# DA14585 register map
Vendor: Dialog; Series: DA1458x; File version: 1.2
CPU: CM0 r1p0, little endian, MPU, FPU, 3 interrupt priority bits
Registers are 16-bit, read-write, reset 0x0 unless marked. A register's access mark holds for its fields unless they carry their own. Offsets are from the block's base; [hi:lo] are bit positions; {n}, {i} and the like mark numbered series.

## UART2 — UART2 registers
Base 0x50001100
0x00 UART2_RBR_THR_DLL_REG — Receive Buffer Register
  [7:0] RBR_THR_DLL — Receive Buffer Register: This register contains the data byte received on the serial input port (sin) in UART mode or the serial infrared input (sir_in) in infrared mode. The data in this register is valid only if the Data Ready (DR) bit in the Line status Register (LSR) is set. If FIFOs are disabled (FCR[0] set to zero), the data in the RBR must be read before the next data arrives, otherwise it will be overwritten, resulting in an overrun error. If FIFOs are enabled (FCR[0] set to one), this register accesses the head of the receive FIFO. If the receive FIFO is full and this register is not read before the next data character arrives, then the data already in the FIFO will be preserved but any incoming data will be lost. An overrun error will also occur. Transmit Holding Register: This register contains data to be transmitted on the serial output port (sout) in UART mode or the serial infrared output (sir_out_n) in infrared mode. Data should only be written to the THR when the THR Empty (THRE) bit (LSR[5]) is set. If FIFO's are disabled (FCR[0] set to zero) and THRE is set, writing a single character to the THR clears the THRE. Any additional writes to the THR before the THRE is set again causes the THR data to be overwritten. If FIFO's are enabled (FCR[0] set to one) and THRE is set, x number of characters of data may be written to the THR before the FIFO is full. The number x (default=16) is determined by the value of FIFO Depth that you set during configuration. Any attempt to write data when the FIFO is full results in the write data being lost. Divisor Latch (Low): This register makes up the lower 8-bits of a 16-bit, read/write, Divisor Latch register that contains the baud rate divisor for the UART. This register may only be accessed when the DLAB bit (LCR[7]) is set. The output baud rate is equal to the serial clock (sclk) frequency divided by sixteen times the value of the baud rate divisor, as follows: baud rate = (serial clock freq) / (16 * divisor) Note that with the Divisor Latch Registers (DLL and DLH) set to zero, the baud clock is disabled and no serial communications will occur. Also, once the DLL is set, at least 8 clock cycles of the slowest DW_apb_uart clock should be allowed to pass before transmitting or receiving data.
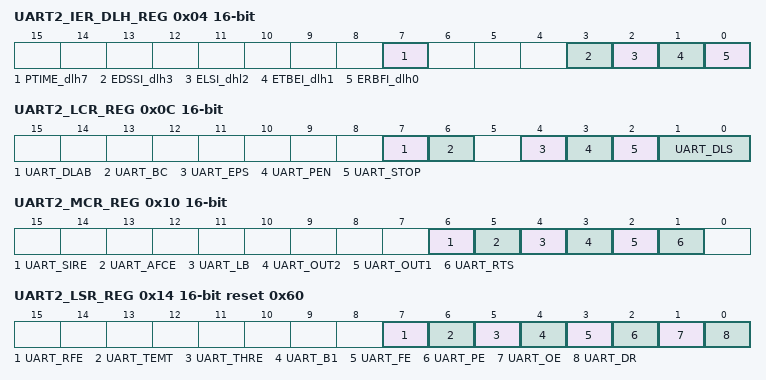
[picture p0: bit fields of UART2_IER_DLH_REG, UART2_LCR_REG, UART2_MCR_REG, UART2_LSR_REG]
0x04 UART2_IER_DLH_REG — Interrupt Enable Register
  [7] PTIME_dlh7 — Interrupt Enable Register: PTIME, Programmable THRE Interrupt Mode Enable. This is used to enable/disable the generation of THRE Interrupt. 0 = disabled 1 = enabled Divisor Latch (High): Bit[7] of the 8 bit DLH register.
  [3] EDSSI_dlh3 — Interrupt Enable Register: EDSSI, Enable Modem Status Interrupt. This is used to enable/disable the generation of Modem Status Interrupt. This is the fourth highest priority interrupt. 0 = disabled 1 = enabled Divisor Latch (High): Bit[3] of the 8 bit DLH register
  [2] ELSI_dhl2 — Interrupt Enable Register: ELSI, Enable Receiver Line Status Interrupt. This is used to enable/disable the generation of Receiver Line Status Interrupt. This is the highest priority interrupt. 0 = disabled 1 = enabled Divisor Latch (High): Bit[2] of the 8 bit DLH register.
  [1] ETBEI_dlh1 — Interrupt Enable Register: ETBEI, Enable Transmit Holding Register Empty Interrupt. This is used to enable/disable the generation of Transmitter Holding Register Empty Interrupt. This is the third highest priority interrupt. 0 = disabled 1 = enabled Divisor Latch (High): Bit[1] of the 8 bit DLH register.
  [0] ERBFI_dlh0 — Interrupt Enable Register: ERBFI, Enable Received Data Available Interrupt. This is used to enable/disable the generation of Received Data Available Interrupt and the Character Timeout Interrupt (if in FIFO mode and FIFO's enabled). These are the second highest priority interrupts. 0 = disabled 1 = enabled Divisor Latch (High): Bit[0] of the 8 bit DLH register.
0x08 UART2_IIR_FCR_REG — Interrupt Identification Register/FIFO Control Register
  [15:0] IIR_FCR — Interrupt Identification Register, reading this register; FIFO Control Register, writing to this register. Interrupt Identification Register: Bits[7:6], FIFO's Enabled (or FIFOSE): This is used to indicate whether the FIFO's are enabled or disabled. 00 = disabled. 11 = enabled. Bits[3:0], Interrupt ID (or IID): This indicates the highest priority pending interrupt which can be one of the following types: 0000 = modem status. 0001 = no interrupt pending. 0010 = THR empty. 0100 = received data available. 0110 = receiver line status. 0111 = busy detect. 1100 = character timeout. Bits[7:6], RCVR Trigger (or RT):. This is used to select the trigger level in the receiver FIFO at which the Received Data Available Interrupt will be generated. In auto flow control mode it is used to determine when the rts_n signal will be de-asserted. It also determines when the dma_rx_req_n signal will be asserted when in certain modes of operation. The following trigger levels are supported: 00 = 1 character in the FIFO 01 = FIFO 1/4 full 10 = FIFO 1/2 full 11 = FIFO 2 less than full Bits[5:4], TX Empty Trigger (or TET): This is used to select the empty threshold level at which the THRE Interrupts will be generated when the mode is active. It also determines when the dma_tx_req_n signal will be asserted when in certain modes of operation. The following trigger levels are supported: 00 = FIFO empty 01 = 2 characters in the FIFO 10 = FIFO 1/4 full 11 = FIFO 1/2 full Bit[3], DMA Mode (or DMAM): This determines the DMA signalling mode used for the dma_tx_req_n and dma_rx_req_n output signals. 0 = mode 0 1 = mode 1 Bit[2], XMIT FIFO Reset (or XFIFOR): This resets the control portion of the transmit FIFO and treats the FIFO as empty. Note that this bit is 'self-clearing' and it is not necessary to clear this bit. Bit[1], RCVR FIFO Reset (or RFIFOR): This resets the control portion of the receive FIFO and treats the FIFO as empty. Note that this bit is 'self-clearing' and it is not necessary to clear this bit. Bit[0], FIFO Enable (or FIFOE): This enables/disables the transmit (XMIT) and receive (RCVR) FIFO's. Whenever the value of this bit is changed both the XMIT and RCVR controller portion of FIFO's will be reset.
0x0C UART2_LCR_REG — Line Control Register
  [7] UART_DLAB — Divisor Latch Access Bit. This bit is used to enable reading and writing of the Divisor Latch register (DLL and DLH) to set the baud rate of the UART. This bit must be cleared after initial baud rate setup in order to access other registers.
  [6] UART_BC — Break Control Bit. This is used to cause a break condition to be transmitted to the receiving device. If set to one the serial output is forced to the spacing (logic 0) state. When not in Loopback Mode, as determined by MCR[4], the sout line is forced low until the Break bit is cleared. If active (MCR[6] set to one) the sir_out_n line is continuously pulsed. When in Loopback Mode, the break condition is internally looped back to the receiver and the sir_out_n line is forced low.
  [4] UART_EPS — Even Parity Select. This is used to select between even and odd parity, when parity is enabled (PEN set to one). If set to one, an even number of logic 1s is transmitted or checked. If set to zero, an odd number of logic 1s is transmitted or checked.
  [3] UART_PEN — Parity Enable. This bit is used to enable and disable parity generation and detection in transmitted and received serial character respectively. 0 = parity disabled 1 = parity enabled
  [2] UART_STOP — Number of stop bits. This is used to select the number of stop bits per character that the peripheral transmits and receives. If set to zero, one stop bit is transmitted in the serial data. If set to one and the data bits are set to 5 (LCR[1:0] set to zero) one and a half stop bits is transmitted. Otherwise, two stop bits are transmitted. Note that regardless of the number of stop bits selected, the receiver checks only the first stop bit. 0 = 1 stop bit 1 = 1.5 stop bits when DLS (LCR[1:0]) is zero, else 2 stop bit
  [1:0] UART_DLS — Data Length Select. This is used to select the number of data bits per character that the peripheral transmits and receives. The number of bit that may be selected areas follows: 00 = 5 bits 01 = 6 bits 10 = 7 bits 11 = 8 bits
0x10 UART2_MCR_REG — Modem Control Register
  [6] UART_SIRE — SIR Mode Enable. This is used to enable or disable the IrDA SIR Mode features as described in 'IrDA 1.0 SIR Protocol' on page 53. 0 = IrDA SIR Mode disabled. 1 = IrDA SIR Mode enabled .
  [5] UART_AFCE — Auto Flow Control Enable. When FIFOs are enabled and the Auto Flow Control Enable (AFCE) bit is set, hardware Auto Flow Control is enabled via CTS and RTS. 0 = Auto Flow Control Mode disabled 1 = Auto Flow Control Mode enabled
  [4] UART_LB — LoopBack Bit. This is used to put the UART into a diagnostic mode for test purposes. If operating in UART mode (SIR_MODE not active, MCR[6] set to zero), data on the sout line is held high, while serial data output is looped back to the sin line, internally. In this mode all the interrupts are fully functional. Also, in loopback mode, the modem control inputs (dsr_n, cts_n, ri_n, dcd_n) are disconnected and the modem control outputs (dtr_n, rts_n, out1_n, out2_n) are looped back to the inputs, internally. If operating in infrared mode (SIR_MODE active, MCR[6] set to one), data on the sir_out_n line is held low, while serial data output is inverted and looped back to the sir_in line.
  [3] UART_OUT2 — OUT2. This is used to directly control the user-designated Output2 (out2_n) output. The value written to this location is inverted and driven out on out2_n, that is: 0 = out2_n de-asserted (logic 1) 1 = out2_n asserted (logic 0) Note that in Loopback mode (MCR[4] set to one), the out2_n output is held inactive high while the value of this location is internally looped back to an input.
  [2] UART_OUT1 — OUT1. This is used to directly control the user-designated Output1 (out1_n) output. The value written to this location is inverted and driven out on out1_n, that is: 0 = out1_n de-asserted (logic 1) 1 = out1_n asserted (logic 0) Note that in Loopback mode (MCR[4] set to one), the out1_n output is held inactive high while the value of this location is internally looped back to an input.
  [1] UART_RTS — Request to Send. This is used to directly control the Request to Send (rts_n) output. The Request To Send (rts_n) output is used to inform the modem or data set that the UART is ready to exchange data. When Auto Flow Control is disabled (MCR[5] set to zero), the rts_n signal is set low by programming MCR[1] (RTS) to a high. When Auto Flow Control is enabled (MCR[5] set to one) and FIFOs are enabled (FCR[0] set to one), the rts_n output is controlled in the same way, but is also gated with the receiver FIFO threshold trigger (rts_n is inactive high when above the threshold). The rts_n signal is de-asserted when MCR[1] is set low. Note that in Loopback mode (MCR[4] set to one), the rts_n output is held inactive (high) while the value of this location is internally looped back to an input.
0x14 UART2_LSR_REG reset 0x60 — Line Status Register
  [7] UART_RFE ro — Receiver FIFO Error bit. This bit is only relevant when FIFOs are enabled (FCR[0] set to one). This is used to indicate if there is at least one parity error, framing error, or break indication in the FIFO. 0 = no error in RX FIFO 1 = error in RX FIFO This bit is cleared when the LSR is read and the character with the error is at the top of the receiver FIFO and there are no subsequent errors in the FIFO.
  [6] UART_TEMT ro — Transmitter Empty bit. If FIFOs enabled (FCR[0] set to one), this bit is set whenever the Transmitter Shift Register and the FIFO are both empty. If FIFOs are disabled, this bit is set whenever the Transmitter Holding Register and the Transmitter Shift Register are both empty.
  [5] UART_THRE ro — Transmit Holding Register Empty bit. If THRE mode is disabled (IER[7] set to zero) and regardless of FIFO's being implemented/enabled or not, this bit indicates that the THR or TX FIFO is empty. This bit is set whenever data is transferred from the THR or TX FIFO to the transmitter shift register and no new data has been written to the THR or TX FIFO. This also causes a THRE Interrupt to occur, if the THRE Interrupt is enabled. If both modes are active (IER[7] set to one and FCR[0] set to one respectively), the functionality is switched to indicate the transmitter FIFO is full, and no longer controls THRE interrupts, which are then controlled by the FCR[5:4] threshold setting.
  [4] UART_B1 ro — Break Interrupt bit. This is used to indicate the detection of a break sequence on the serial input data. If in UART mode (SIR_MODE == Disabled), it is set whenever the serial input, sin, is held in a logic '0' state for longer than the sum of start time + data bits + parity + stop bits. If in infrared mode (SIR_MODE == Enabled), it is set whenever the serial input, sir_in, is continuously pulsed to logic '0' for longer than the sum of start time + data bits + parity + stop bits. A break condition on serial input causes one and only one character, consisting of all zeros, to be received by the UART. In the FIFO mode, the character associated with the break condition is carried through the FIFO and is revealed when the character is at the top of the FIFO. Reading the LSR clears the BI bit. In the non-FIFO mode, the BI indication occurs immediately and persists until the LSR is read.
  [3] UART_FE ro — Framing Error bit. This is used to indicate the occurrence of a framing error in the receiver. A framing error occurs when the receiver does not detect a valid STOP bit in the received data. In the FIFO mode, since the framing error is associated with a character received, it is revealed when the character with the framing error is at the top of the FIFO. When a framing error occurs, the UART tries to resynchronize. It does this by assuming that the error was due to the start bit of the next character and then continues receiving the other bit i.e. data, and/or parity and stop. It should be noted that the Framing Error (FE) bit (LSR[3]) is set if a break interrupt has occurred, as indicated by Break Interrupt (BI) bit (LSR[4]). 0 = no framing error 1 = framing error Reading the LSR clears the FE bit.
  [2] UART_PE ro — Parity Error bit. This is used to indicate the occurrence of a parity error in the receiver if the Parity Enable (PEN) bit (LCR[3]) is set. In the FIFO mode, since the parity error is associated with a character received, it is revealed when the character with the parity error arrives at the top of the FIFO. It should be noted that the Parity Error (PE) bit (LSR[2]) is set if a break interrupt has occurred, as indicated by Break Interrupt (BI) bit (LSR[4]). 0 = no parity error 1 = parity error Reading the LSR clears the PE bit.
  [1] UART_OE ro — Overrun error bit. This is used to indicate the occurrence of an overrun error. This occurs if a new data character was received before the previous data was read. In the non-FIFO mode, the OE bit is set when a new character arrives in the receiver before the previous character was read from the RBR. When this happens, the data in the RBR is overwritten. In the FIFO mode, an overrun error occurs when the FIFO is full and a new character arrives at the receiver. The data in the FIFO is retained and the data in the receive shift register is lost. 0 = no overrun error 1 = overrun error Reading the LSR clears the OE bit.
  [0] UART_DR ro — Data Ready bit. This is used to indicate that the receiver contains at least one character in the RBR or the receiver FIFO. 0 = no data ready 1 = data ready This bit is cleared when the RBR is read in non-FIFO mode, or when the receiver FIFO is empty, in FIFO mode.
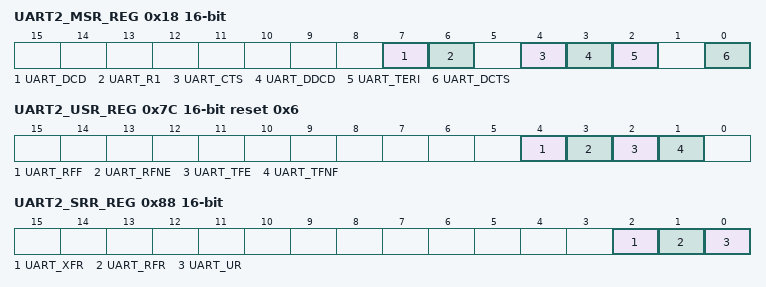
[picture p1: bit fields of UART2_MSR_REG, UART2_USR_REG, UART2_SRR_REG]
0x18 UART2_MSR_REG — Modem Status Register
  [7] UART_DCD ro — Data Carrier Detect. This is used to indicate the current state of the modem control line dcd_n. This bit is the complement of dcd_n. When the Data Carrier Detect input (dcd_n) is asserted it is an indication that the carrier has been detected by the modem or data set. 0 = dcd_n input is de-asserted (logic 1) 1 = dcd_n input is asserted (logic 0) In Loopback Mode (MCR[4] set to one), DCD is the same as MCR[3] (Out2).
  [6] UART_R1 ro — Ring Indicator. This is used to indicate the current state of the modem control line ri_n. This bit is the complement of ri_n. When the Ring Indicator input (ri_n) is asserted it is an indication that a telephone ringing signal has been received by the modem or data set. 0 = ri_n input is de-asserted (logic 1) 1 = ri_n input is asserted (logic 0) In Loopback Mode (MCR[4] set to one), RI is the same as MCR[2] (Out1).
  [4] UART_CTS ro — Clear to Send. This is used to indicate the current state of the modem control line cts_n. This bit is the complement of cts_n. When the Clear to Send input (cts_n) is asserted it is an indication that the modem or data set is ready to exchange data with the UART Ctrl. 0 = cts_n input is de-asserted (logic 1) 1 = cts_n input is asserted (logic 0) In Loopback Mode (MCR[4] = 1), CTS is the same as MCR[1] (RTS).
  [3] UART_DDCD ro — Delta Data Carrier Detect. This is used to indicate that the modem control line dcd_n has changed since the last time the MSR was read. 0 = no change on dcd_n since last read of MSR 1 = change on dcd_n since last read of MSR Reading the MSR clears the DDCD bit. In Loopback Mode (MCR[4] = 1), DDCD reflects changes on MCR[3] (Out2). Note, if the DDCD bit is not set and the dcd_n signal is asserted (low) and a reset occurs (software or otherwise), then the DDCD bit is set when the reset is removed if the dcd_n signal remains asserted.
  [2] UART_TERI ro — Trailing Edge of Ring Indicator. This is used to indicate that a change on the input ri_n (from an active-low to an inactive-high state) has occurred since the last time the MSR was read. 0 = no change on ri_n since last read of MSR 1 = change on ri_n since last read of MSR Reading the MSR clears the TERI bit. In Loopback Mode (MCR[4] = 1), TERI reflects when MCR[2] (Out1) has changed state from a high to a low.
  [0] UART_DCTS ro — Delta Clear to Send. This is used to indicate that the modem control line cts_n has changed since the last time the MSR was read. 0 = no change on cts_n since last read of MSR 1 = change on cts_n since last read of MSR Reading the MSR clears the DCTS bit. In Loopback Mode (MCR[4] = 1), DCTS reflects changes on MCR[1] (RTS). Note, if the DCTS bit is not set and the cts_n signal is asserted (low) and a reset occurs (software or otherwise), then the DCTS bit is set when the reset is removed if the cts_n signal remains asserted.
0x1C UART2_SCR_REG — Scratchpad Register
  [7:0] UART_SCRATCH_PAD — This register is for programmers to use as a temporary storage space. It has no defined purpose in the UART Ctrl.
0x20 UART2_LPDLL_REG — Low Power Divisor Latch Low
  [7:0] UART_LPDLL — This register makes up the lower 8-bits of a 16-bit, read/write, Low Power Divisor Latch register that contains the baud rate divisor for the UART, which must give a baud rate of 115.2K. This is required for SIR Low Power (minimum pulse width) detection at the receiver. This register may be accessed only when the DLAB bit (LCR[7]) is set. The output low-power baud rate is equal to the serial clock (sclk) frequency divided by sixteen times the value of the baud rate divisor, as follows: Low power baud rate = (serial clock frequency)/(16* divisor) Therefore, a divisor must be selected to give a baud rate of 115.2K. NOTE: When the Low Power Divisor Latch registers (LPDLL and LPDLH) are set to 0, the low-power baud clock is disabled and no low-power pulse detection (or any pulse detection) occurs at the receiver. Also, once the LPDLL is set, at least eight clock cycles of the slowest UART Ctrl clock should be allowed to pass before transmitting or receiving data.
0x24 UART2_LPDLH_REG — Low Power Divisor Latch High
  [7:0] UART_LPDLH — This register makes up the upper 8-bits of a 16-bit, read/write, Low Power Divisor Latch register that contains the baud rate divisor for the UART, which must give a baud rate of 115.2K. This is required for SIR Low Power (minimum pulse width) detection at the receiver. This register may be accessed only when the DLAB bit (LCR[7]) is set. The output low-power baud rate is equal to the serial clock (sclk) frequency divided by sixteen times the value of the baud rate divisor, as follows: Low power baud rate = (serial clock frequency)/(16* divisor) Therefore, a divisor must be selected to give a baud rate of 115.2K. NOTE: When the Low Power Divisor Latch registers (LPDLL and LPDLH) are set to 0, the low-power baud clock is disabled and no low-power pulse detection (or any pulse detection) occurs at the receiver. Also, once the LPDLH is set, at least eight clock cycles of the slowest UART Ctrl clock should be allowed to pass before transmitting or receiving data.
{0x30+4i} UART2_SRBR_STHR{i}_REG (i=0..15) — Shadow Receive/Transmit Buffer Register
  [7:0] SRBR_STHRx — Shadow Receive Buffer Register x: This is a shadow register for the RBR and has been allocated sixteen 32-bit locations so as to accommodate burst accesses from the master. This register contains the data byte received on the serial input port (sin) in UART mode or the serial infrared input (sir_in) in infrared mode. The data in this register is valid only if the Data Ready (DR) bit in the Line status Register (LSR) is set. If FIFOs are disabled (FCR[0] set to zero), the data in the RBR must be read before the next data arrives, otherwise it will be overwritten, resulting in an overrun error. If FIFOs are enabled (FCR[0] set to one), this register accesses the head of the receive FIFO. If the receive FIFO is full and this register is not read before the next data character arrives, then the data already in the FIFO will be preserved but any incoming data will be lost. An overrun error will also occur. Shadow Transmit Holding Register 0: This is a shadow register for the THR and has been allocated sixteen 32-bit locations so as to accommodate burst accesses from the master. This register contains data to be transmitted on the serial output port (sout) in UART mode or the serial infrared output (sir_out_n) in infrared mode. Data should only be written to the THR when the THR Empty (THRE) bit (LSR[5]) is set. If FIFO's are disabled (FCR[0] set to zero) and THRE is set, writing a single character to the THR clears the THRE. Any additional writes to the THR before the THRE is set again causes the THR data to be overwritten. If FIFO's are enabled (FCR[0] set to one) and THRE is set, x number of characters of data may be written to the THR before the FIFO is full. The number x (default=16) is determined by the value of FIFO Depth that you set during configuration. Any attempt to write data when the FIFO is full results in the write data being lost.
0x7C UART2_USR_REG reset 0x6 — UART Status register.
  [4] UART_RFF ro — Receive FIFO Full. This is used to indicate that the receive FIFO is completely full. 0 = Receive FIFO not full 1 = Receive FIFO Full This bit is cleared when the RX FIFO is no longer full.
  [3] UART_RFNE ro — Receive FIFO Not Empty. This is used to indicate that the receive FIFO contains one or more entries. 0 = Receive FIFO is empty 1 = Receive FIFO is not empty This bit is cleared when the RX FIFO is empty.
  [2] UART_TFE ro — Transmit FIFO Empty. This is used to indicate that the transmit FIFO is completely empty. 0 = Transmit FIFO is not empty 1 = Transmit FIFO is empty This bit is cleared when the TX FIFO is no longer empty.
  [1] UART_TFNF ro — Transmit FIFO Not Full. This is used to indicate that the transmit FIFO in not full. 0 = Transmit FIFO is full 1 = Transmit FIFO is not full This bit is cleared when the TX FIFO is full.
0x80 UART2_TFL_REG — Transmit FIFO Level
  [15:0] UART_TRANSMIT_FIFO_LEVEL ro — Transmit FIFO Level. This is indicates the number of data entries in the transmit FIFO.
0x84 UART2_RFL_REG — Receive FIFO Level.
  [15:0] UART_RECEIVE_FIFO_LEVEL ro — Receive FIFO Level. This is indicates the number of data entries in the receive FIFO.
0x88 UART2_SRR_REG — Software Reset Register.
  [2] UART_XFR wo — XMIT FIFO Reset. This is a shadow register for the XMIT FIFO Reset bit (FCR[2]). This can be used to remove the burden on software having to store previously written FCR values (which are pretty static) just to reset the transmit FIFO. This resets the control portion of the transmit FIFO and treats the FIFO as empty. Note that this bit is 'self-clearing'. It is not necessary to clear this bit.
  [1] UART_RFR wo — RCVR FIFO Reset. This is a shadow register for the RCVR FIFO Reset bit (FCR[1]). This can be used to remove the burden on software having to store previously written FCR values (which are pretty static) just to reset the receive FIFO This resets the control portion of the receive FIFO and treats the FIFO as empty. Note that this bit is 'self-clearing'. It is not necessary to clear this bit.
  [0] UART_UR wo — UART Reset. This asynchronously resets the UART Ctrl and synchronously removes the reset assertion. For a two clock implementation both pclk and sclk domains are reset.
0x8C UART2_SRTS_REG — Shadow Request to Send
  [0] UART_SHADOW_REQUEST_TO_SEND — Shadow Request to Send. This is a shadow register for the RTS bit (MCR[1]), this can be used to remove the burden of having to perform a read-modify-write on the MCR. This is used to directly control the Request to Send (rts_n) output. The Request To Send (rts_n) output is used to inform the modem or data set that the UART Ctrl is ready to exchange data. When Auto Flow Control is disabled (MCR[5] = 0), the rts_n signal is set low by programming MCR[1] (RTS) to a high. When Auto Flow Control is enabled (MCR[5] = 1) and FIFOs are enabled (FCR[0] = 1), the rts_n output is controlled in the same way, but is also gated with the receiver FIFO threshold trigger (rts_n is inactive high when above the threshold). Note that in Loopback mode (MCR[4] = 1), the rts_n output is held inactive-high while the value of this location is internally looped back to an input.
0x90 UART2_SBCR_REG — Shadow Break Control Register
  [0] UART_SHADOW_BREAK_CONTROL — Shadow Break Control Bit. This is a shadow register for the Break bit (LCR[6]), this can be used to remove the burden of having to performing a read modify write on the LCR. This is used to cause a break condition to be transmitted to the receiving device. If set to one the serial output is forced to the spacing (logic 0) state. When not in Loopback Mode, as determined by MCR[4], the sout line is forced low until the Break bit is cleared. If SIR_MODE active (MCR[6] = 1) the sir_out_n line is continuously pulsed. When in Loopback Mode, the break condition is internally looped back to the receiver.
0x94 UART2_SDMAM_REG — Shadow DMA Mode
  [0] UART_SHADOW_DMA_MODE — Shadow DMA Mode. This is a shadow register for the DMA mode bit (FCR[3]). This can be used to remove the burden of having to store the previously written value to the FCR in memory and having to mask this value so that only the DMA Mode bit gets updated. This determines the DMA signalling mode used for the dma_tx_req_n and dma_rx_req_n output signals. 0 = mode 0 1 = mode 1
0x98 UART2_SFE_REG — Shadow FIFO Enable
  [0] UART_SHADOW_FIFO_ENABLE — Shadow FIFO Enable. This is a shadow register for the FIFO enable bit (FCR[0]). This can be used to remove the burden of having to store the previously written value to the FCR in memory and having to mask this value so that only the FIFO enable bit gets updated.This enables/disables the transmit (XMIT) and receive (RCVR) FIFOs. If this bit is set to zero (disabled) after being enabled then both the XMIT and RCVR controller portion of FIFOs are reset.
0x9C UART2_SRT_REG — Shadow RCVR Trigger
  [1:0] UART_SHADOW_RCVR_TRIGGER — Shadow RCVR Trigger. This is a shadow register for the RCVR trigger bits (FCR[7:6]). This can be used to remove the burden of having to store the previously written value to the FCR in memory and having to mask this value so that only the RCVR trigger bit gets updated. This is used to select the trigger level in the receiver FIFO at which the Received Data Available Interrupt is generated. It also determines when the dma_rx_req_n signal is asserted when DMA Mode (FCR[3]) = 1. The following trigger levels are supported: 00 = 1 character in the FIFO 01 = FIFO Â¼ full 10 = FIFO Â½ full 11 = FIFO 2 less than full
0xA0 UART2_STET_REG — Shadow TX Empty Trigger
  [1:0] UART_SHADOW_TX_EMPTY_TRIGGER — Shadow TX Empty Trigger. This is a shadow register for the TX empty trigger bits (FCR[5:4]). This can be used to remove the burden of having to store the previously written value to the FCR in memory and having to mask this value so that only the TX empty trigger bit gets updated. This is used to select the empty threshold level at which the THRE Interrupts are generated when the mode is active. The following trigger levels are supported: 00 = FIFO empty 01 = 2 characters in the FIFO 10 = FIFO Â¼ full 11 = FIFO Â½ full
0xA4 UART2_HTX_REG — Halt TX
  [0] UART_HALT_TX — This register is use to halt transmissions for testing, so that the transmit FIFO can be filled by the master when FIFOs are implemented and enabled. 0 = Halt TX disabled 1 = Halt TX enabled Note, if FIFOs are implemented and not enabled, the setting of the halt TX register has no effect on operation.
0xF4 UART2_CPR_REG — Component Parameter Register
  [15:0] CPR ro
0xF8 UART2_UCV_REG reset 0x3330382A — Component Version
  [15:0] UCV ro
0xFC UART2_CTR_REG reset 0x44570110 — Component Type Register
  [15:0] CTR ro
